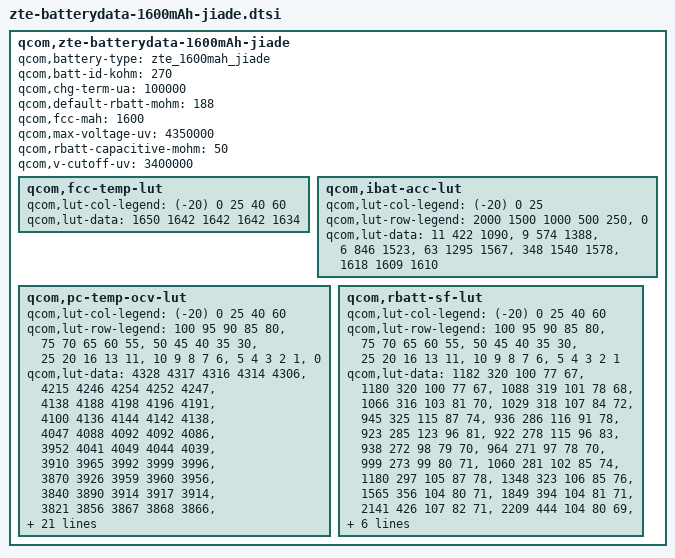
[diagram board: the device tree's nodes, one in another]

qcom,zte-batterydata-1600mAh-jiade {
	qcom,battery-type = "zte_1600mah_jiade";
	qcom,batt-id-kohm = <270>;
	qcom,chg-term-ua = <100000>;
	qcom,default-rbatt-mohm = <188>;
	qcom,fcc-mah = <1600>;
	qcom,max-voltage-uv = <4350000>;
	qcom,rbatt-capacitive-mohm = <50>;
	qcom,v-cutoff-uv = <3400000>;

	qcom,fcc-temp-lut {
		qcom,lut-col-legend = <(-20) 0 25 40 60>;
		qcom,lut-data = <1650 1642 1642 1642 1634>;
	};

	qcom,ibat-acc-lut {
		qcom,lut-col-legend = <(-20) 0 25>;
		qcom,lut-row-legend = <2000 1500 1000 500 250>,
					<0>;
		qcom,lut-data = <11 422 1090>,
				<9 574 1388>,
				<6 846 1523>,
				<63 1295 1567>,
				<348 1540 1578>,
				<1618 1609 1610>;
	};

	qcom,pc-temp-ocv-lut {
		qcom,lut-col-legend = <(-20) 0 25 40 60>;
		qcom,lut-row-legend = <100 95 90 85 80>,
					<75 70 65 60 55>,
					<50 45 40 35 30>,
					<25 20 16 13 11>,
					<10 9 8 7 6>,
					<5 4 3 2 1>,
					<0>;
		qcom,lut-data = <4328 4317 4316 4314 4306>,
				<4215 4246 4254 4252 4247>,
				<4138 4188 4198 4196 4191>,
				<4100 4136 4144 4142 4138>,
				<4047 4088 4092 4092 4086>,
				<3952 4041 4049 4044 4039>,
				<3910 3965 3992 3999 3996>,
				<3870 3926 3959 3960 3956>,
				<3840 3890 3914 3917 3914>,
				<3821 3856 3867 3868 3866>,
				<3806 3828 3838 3839 3838>,
				<3793 3806 3816 3817 3816>,
				<3780 3790 3798 3799 3798>,
				<3766 3780 3783 3783 3781>,
				<3751 3770 3770 3766 3760>,
				<3736 3757 3755 3746 3734>,
				<3718 3739 3736 3727 3713>,
				<3702 3718 3715 3707 3693>,
				<3689 3704 3694 3686 3673>,
				<3676 3696 3688 3681 3670>,
				<3668 3692 3687 3680 3669>,
				<3657 3689 3686 3679 3668>,
				<3644 3686 3684 3678 3666>,
				<3626 3680 3681 3674 3661>,
				<3602 3665 3670 3660 3642>,
				<3572 3636 3640 3628 3606>,
				<3529 3589 3592 3580 3558>,
				<3470 3524 3531 3519 3496>,
				<3382 3432 3448 3437 3413>,
				<3241 3289 3321 3311 3283>,
				<3034 3018 3010 3016 3010>;
	};

	qcom,rbatt-sf-lut {
		qcom,lut-col-legend = <(-20) 0 25 40 60>;
		qcom,lut-row-legend = <100 95 90 85 80>,
					<75 70 65 60 55>,
					<50 45 40 35 30>,
					<25 20 16 13 11>,
					<10 9 8 7 6>,
					<5 4 3 2 1>;
		qcom,lut-data = <1182 320 100 77 67>,
				<1180 320 100 77 67>,
				<1088 319 101 78 68>,
				<1066 316 103 81 70>,
				<1029 318 107 84 72>,
				<945 325 115 87 74>,
				<936 286 116 91 78>,
				<923 285 123 96 81>,
				<922 278 115 96 83>,
				<938 272 98 79 70>,
				<964 271 97 78 70>,
				<999 273 99 80 71>,
				<1060 281 102 85 74>,
				<1180 297 105 87 78>,
				<1348 323 106 85 76>,
				<1565 356 104 80 71>,
				<1849 394 104 81 71>,
				<2141 426 107 82 71>,
				<2209 444 104 80 69>,
				<2435 448 104 79 70>,
				<2613 465 106 81 71>,
				<2812 487 109 83 73>,
				<3084 511 113 86 74>,
				<3391 535 118 88 76>,
				<3785 560 119 88 73>,
				<4324 582 116 85 73>,
				<5030 619 119 86 74>,
				<6101 691 127 90 79>,
				<7967 877 139 101 87>,
				<15934 1753 194 148 123>;
	};
};
